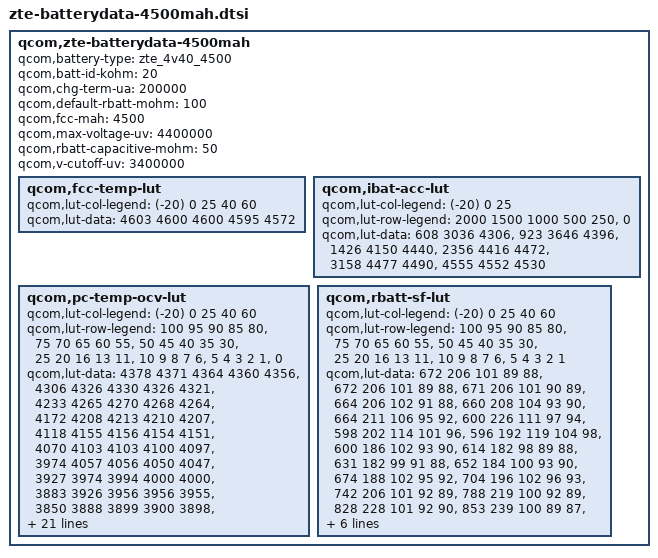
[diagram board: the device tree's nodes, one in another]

qcom,zte-batterydata-4500mah {
	qcom,battery-type = "zte_4v40_4500";
	qcom,batt-id-kohm = <20>;
	qcom,chg-term-ua = <200000>;
	qcom,default-rbatt-mohm = <100>;
	qcom,fcc-mah = <4500>;
	qcom,max-voltage-uv = <4400000>;
	qcom,rbatt-capacitive-mohm = <50>;
	qcom,v-cutoff-uv = <3400000>;

	qcom,fcc-temp-lut {
		qcom,lut-col-legend = <(-20) 0 25 40 60>;
		qcom,lut-data = <4603 4600 4600 4595 4572>;
	};

	qcom,ibat-acc-lut {
		qcom,lut-col-legend = <(-20) 0 25>;
		qcom,lut-row-legend = <2000 1500 1000 500 250>,
					<0>;
		qcom,lut-data = <608 3036 4306>,
				<923 3646 4396>,
				<1426 4150 4440>,
				<2356 4416 4472>,
				<3158 4477 4490>,
				<4555 4552 4530>;
	};

	qcom,pc-temp-ocv-lut {
		qcom,lut-col-legend = <(-20) 0 25 40 60>;
		qcom,lut-row-legend = <100 95 90 85 80>,
					<75 70 65 60 55>,
					<50 45 40 35 30>,
					<25 20 16 13 11>,
					<10 9 8 7 6>,
					<5 4 3 2 1>,
					<0>;
		qcom,lut-data = <4378 4371 4364 4360 4356>,
				<4306 4326 4330 4326 4321>,
				<4233 4265 4270 4268 4264>,
				<4172 4208 4213 4210 4207>,
				<4118 4155 4156 4154 4151>,
				<4070 4103 4103 4100 4097>,
				<3974 4057 4056 4050 4047>,
				<3927 3974 3994 4000 4000>,
				<3883 3926 3956 3956 3955>,
				<3850 3888 3899 3900 3898>,
				<3829 3855 3862 3862 3862>,
				<3812 3828 3835 3835 3834>,
				<3796 3806 3813 3814 3812>,
				<3782 3790 3795 3795 3793>,
				<3766 3779 3778 3776 3771>,
				<3750 3766 3759 3751 3740>,
				<3734 3749 3739 3730 3717>,
				<3720 3728 3718 3709 3696>,
				<3708 3710 3698 3689 3678>,
				<3698 3700 3690 3683 3671>,
				<3692 3697 3689 3681 3670>,
				<3684 3694 3688 3680 3668>,
				<3676 3692 3686 3678 3667>,
				<3664 3688 3683 3675 3664>,
				<3646 3681 3676 3667 3652>,
				<3621 3662 3652 3639 3620>,
				<3590 3622 3606 3592 3574>,
				<3540 3564 3546 3532 3512>,
				<3470 3483 3464 3448 3429>,
				<3354 3356 3340 3318 3302>,
				<3000 3042 3034 3000 3000>;
	};

	qcom,rbatt-sf-lut {
		qcom,lut-col-legend = <(-20) 0 25 40 60>;
		qcom,lut-row-legend = <100 95 90 85 80>,
					<75 70 65 60 55>,
					<50 45 40 35 30>,
					<25 20 16 13 11>,
					<10 9 8 7 6>,
					<5 4 3 2 1>;
		qcom,lut-data = <672 206 101 89 88>,
				<672 206 101 89 88>,
				<671 206 101 90 89>,
				<664 206 102 91 88>,
				<660 208 104 93 90>,
				<664 211 106 95 92>,
				<600 226 111 97 94>,
				<598 202 114 101 96>,
				<596 192 119 104 98>,
				<600 186 102 93 90>,
				<614 182 98 89 88>,
				<631 182 99 91 88>,
				<652 184 100 93 90>,
				<674 188 102 95 92>,
				<704 196 102 96 93>,
				<742 206 101 92 89>,
				<788 219 100 92 89>,
				<828 228 101 92 90>,
				<853 239 100 89 87>,
				<851 242 100 89 88>,
				<866 248 102 91 91>,
				<886 256 104 93 95>,
				<905 266 106 97 99>,
				<926 277 110 102 102>,
				<946 286 114 102 100>,
				<969 292 108 95 93>,
				<1008 294 106 93 91>,
				<1046 307 107 95 93>,
				<1153 331 111 97 95>,
				<1754 368 122 112 110>;
	};
};
/* TEST_DB_ID=TEST_ID_NOT_SET */
